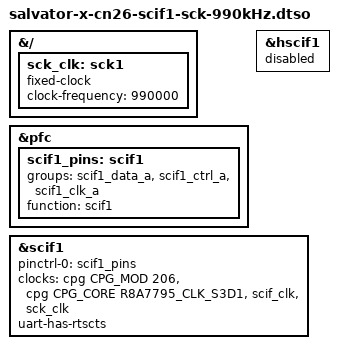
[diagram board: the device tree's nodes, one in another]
// SPDX-License-Identifier: GPL-2.0
//
// Device Tree Overlay for SCIF1 on Salvator-X(S) Debug Serial 1 (CN26), with
// 990 kHz SCK input on EXIO B.
//
// Copyright (C) 2015 Glider bvba
//
// Notes:
//   - As these pins are shared with HSCIF1, the latter is disabled first.
//
// EXIO Pinout:
//   - TXD = EXIO B pin 55
//   - RXD = EXIO B pin 53 [*]
//   - RTS = EXIO B pin 49
//   - CTS = EXIO B pin 47 [*]
//   - SCK = EXIO B pin 57
//   - 3V3 = EXIO B pin 41
//   - GND = EXIO B pin 63
//
// [*] As these pins are driven by buffers connected to the CP2102, they can
//     be used for monitoring only, and not serve as inputs!

/dts-v1/;
/plugin/;

#include <dt-bindings/clock/r8a7795-cpg-mssr.h>

&{/} {
	sck_clk: sck1 {
		/* 74HC14 oscillator, R = 15K/2, C = 120J */
		compatible = "fixed-clock";
		#clock-cells = <0>;
		clock-frequency = <990000>;
		status = "okay";
	};
};

&pfc {
	scif1_pins: scif1 {
		groups = "scif1_data_a", "scif1_ctrl_a",
			 "scif1_clk_a";
		function = "scif1";
	};
};

&hscif1 {
	status = "disabled";
};

&scif1 {
	pinctrl-0 = <&scif1_pins>;
	pinctrl-names = "default";

	clocks = <&cpg CPG_MOD 206>,
		 <&cpg CPG_CORE R8A7795_CLK_S3D1>,
		 <&scif_clk>, <&sck_clk>;
	clock-names = "fck", "brg_int", "scif_clk", "sck";

	uart-has-rtscts;
	status = "okay";
};
